# f28e12x_pga_regs register map
Vendor: Texas Instruments
Peripheral module from a debugger description file (folder C2000).
Address unit: 16 bits
Registers are 16-bit, read-write, no defined reset value unless marked. A register's access mark holds for its fields unless they carry their own. Offsets are as the file gives them; lines under a group give offsets from that group; [hi:lo] are bit positions; {n}, {i} and the like mark numbered series; 'fields as' and 'values as' point back to an identical list; <NAME> marks a mode.

## PGA_REGS — PGA Registers
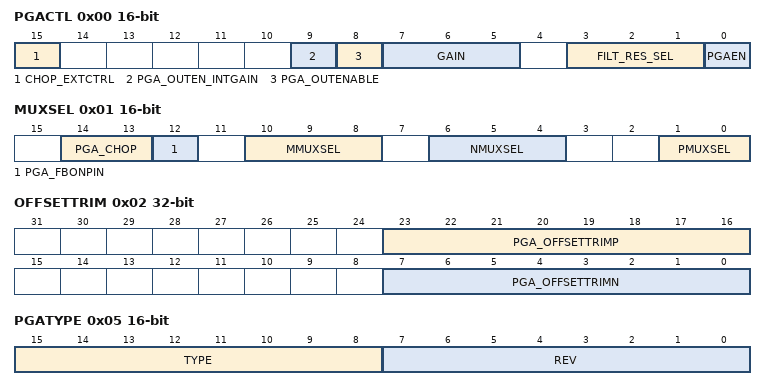
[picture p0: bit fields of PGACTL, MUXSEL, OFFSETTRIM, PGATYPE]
0x00 PGACTL — PGA Control Register
  [15] CHOP_EXTCTRL — External Chop Signal Control
  [9] PGA_OUTEN_INTGAIN — PGA Internal Gain Output Enable
  [8] PGA_OUTENABLE — PGA Output Enable
  [7:5] GAIN — PGA gain setting
  [3:1] FILT_RES_SEL — Filter Resistor Select
  [0] PGAEN — PGA Enable
0x01 MUXSEL — Mux Selection Register
  [14:13] PGA_CHOP — Chopper Mode Control
  [12] PGA_FBONPIN — Connect PGAOUT to PGA_INM
  [10:8] MMUXSEL — M Mux Select
  [6:4] NMUXSEL — Negative Input Mux Select
  [1:0] PMUXSEL — Positive Input Mux Select
0x02 OFFSETTRIM 32-bit
  [23:16] PGA_OFFSETTRIMP — OFFSET TRIM value for i/p PMOS pair
  [7:0] PGA_OFFSETTRIMN — OFFSET TRIM value for i/p NMOS pair
0x05 PGATYPE ro
  [15:8] TYPE — PGA Type Field
  [7:0] REV — PGA Revision Field
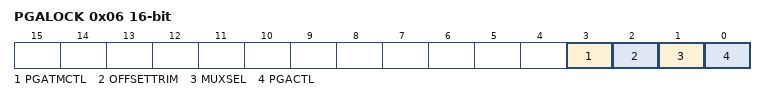
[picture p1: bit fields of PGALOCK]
0x06 PGALOCK
  [3] PGATMCTL — Lock but for PGATMCTL
  [2] OFFSETTRIM — Lock bit for OFFSET TRIM
  [1] MUXSEL — Lock bit for MUXSEL
  [0] PGACTL — Lock bit for PGACTL.
